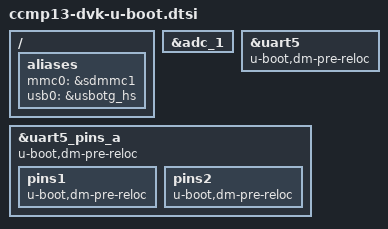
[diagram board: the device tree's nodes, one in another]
// SPDX-License-Identifier: GPL-2.0-or-later OR BSD-3-Clause
/*
 * Copyright (C) 2022, Digi International Inc - All Rights Reserved
 */

#include "stm32mp13-u-boot.dtsi"

/ {
	aliases {
		mmc0 = &sdmmc1;
		usb0 = &usbotg_hs;
	};
};

&adc_1 {
	status = "okay";
};

&uart5 {
	u-boot,dm-pre-reloc;
};

&uart5_pins_a {
	u-boot,dm-pre-reloc;
	pins1 {
		u-boot,dm-pre-reloc;
	};
	pins2 {
		u-boot,dm-pre-reloc;
	};
};
